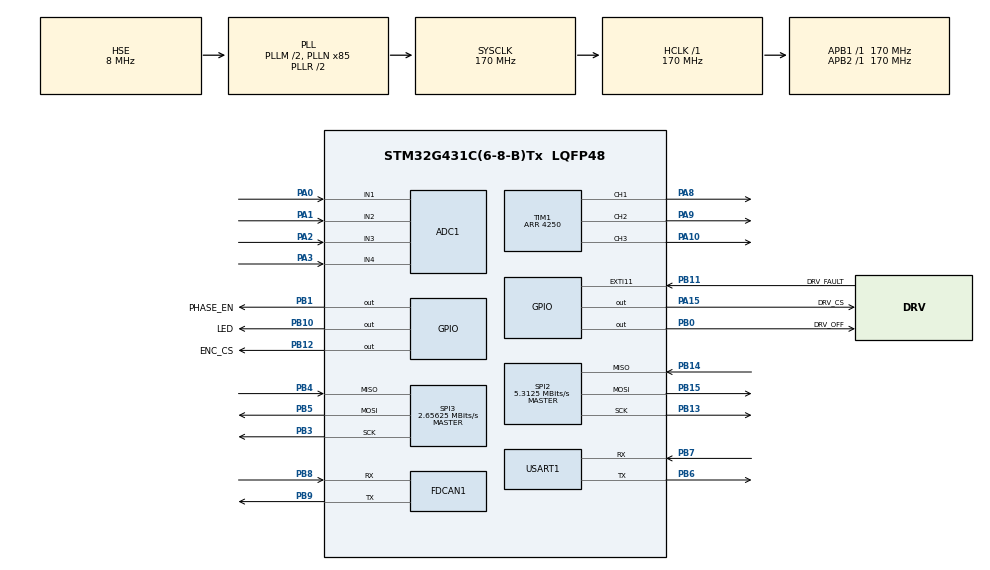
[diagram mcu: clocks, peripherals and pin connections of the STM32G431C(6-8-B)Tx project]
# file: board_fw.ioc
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ADC1.Channel-0\#ChannelRegularConversion=ADC_CHANNEL_4
ADC1.EOCSelection=ADC_EOC_SEQ_CONV
ADC1.EnableInjectedConversion=ENABLE
ADC1.ExternalTrigInjecConv=ADC_EXTERNALTRIGINJEC_T1_CC4
ADC1.InjNumberOfConversion=3
ADC1.InjectedChannel-1\#ChannelInjectedConversion=ADC_CHANNEL_1
ADC1.InjectedChannel-2\#ChannelInjectedConversion=ADC_CHANNEL_2
ADC1.InjectedChannel-3\#ChannelInjectedConversion=ADC_CHANNEL_3
ADC1.InjectedOffsetNumber-1\#ChannelInjectedConversion=ADC_OFFSET_NONE
ADC1.InjectedOffsetNumber-2\#ChannelInjectedConversion=ADC_OFFSET_NONE
ADC1.InjectedOffsetNumber-3\#ChannelInjectedConversion=ADC_OFFSET_NONE
ADC1.InjectedRank-1\#ChannelInjectedConversion=1
ADC1.InjectedRank-2\#ChannelInjectedConversion=2
ADC1.InjectedRank-3\#ChannelInjectedConversion=3
ADC1.InjectedSamplingTime-1\#ChannelInjectedConversion=ADC_SAMPLETIME_12CYCLES_5
ADC1.InjectedSamplingTime-2\#ChannelInjectedConversion=ADC_SAMPLETIME_12CYCLES_5
ADC1.InjectedSamplingTime-3\#ChannelInjectedConversion=ADC_SAMPLETIME_12CYCLES_5
ADC1.NbrOfConversionFlag=1
ADC1.OffsetNumber-0\#ChannelRegularConversion=ADC_OFFSET_NONE
ADC1.Rank-0\#ChannelRegularConversion=1
ADC1.Rank1_Channel=ADC_CHANNEL_1
ADC1.Rank2_Channel=ADC_CHANNEL_2
ADC1.Rank3_Channel=ADC_CHANNEL_3
ADC1.SamplingTime-0\#ChannelRegularConversion=ADC_SAMPLETIME_247CYCLES_5
ADC1.master=1
FDCAN1.CalculateBaudRateNominal=999999
FDCAN1.CalculateTimeBitNominal=1000
FDCAN1.CalculateTimeQuantumNominal=58.82352941176471
FDCAN1.NominalPrescaler=10
FDCAN1.NominalSyncJumpWidth=3
FDCAN1.NominalTimeSeg1=13
FDCAN1.NominalTimeSeg2=3
IWDG.Prescaler=IWDG_PRESCALER_64
IWDG.Reload=999
Mcu.Family=STM32G4
Mcu.Name=STM32G431C(6-8-B)Tx
Mcu.Package=LQFP48
NVIC.ADC1_2_IRQn=true\:0\:0\:false\:false\:true\:true\:true\:true
NVIC.EXTI15_10_IRQn=true\:0\:0\:false\:false\:true\:true\:true\:true
NVIC.FDCAN1_IT0_IRQn=true\:0\:0\:false\:false\:true\:true\:true\:true
NVIC.PriorityGroup=NVIC_PRIORITYGROUP_4
NVIC.TIM6_DAC_IRQn=true\:15\:0\:false\:false\:true\:false\:true\:true
NVIC.TimeBase=TIM6_DAC_IRQn
NVIC.TimeBaseIP=TIM6
NVIC.USART1_IRQn=true\:0\:0\:false\:false\:true\:true\:true\:true
PA0.Mode=IN1-Single-Ended
PA0.Signal=ADC1_IN1
PA1.Mode=IN2-Single-Ended
PA1.Signal=ADC1_IN2
PA10.Signal=S_TIM1_CH3
PA13.Mode=Serial_Wire
PA13.Signal=SYS_JTMS-SWDIO
PA14.Mode=Serial_Wire
PA14.Signal=SYS_JTCK-SWCLK
PA15.GPIO_Label=DRV_CS
PA15.PinState=GPIO_PIN_SET
PA15.Signal=GPIO_Output
PA2.Mode=IN3-Single-Ended
PA2.Signal=ADC1_IN3
PA3.Mode=IN4-Single-Ended
PA3.Signal=ADC1_IN4
PA8.Signal=S_TIM1_CH1
PA9.Signal=S_TIM1_CH2
PB0.GPIO_Label=DRV_OFF
PB0.PinState=GPIO_PIN_SET
PB0.Signal=GPIO_Output
PB1.GPIO_Label=PHASE_EN
PB1.Signal=GPIO_Output
PB10.GPIO_Label=LED
PB10.Signal=GPIO_Output
PB11.GPIO_Label=DRV_FAULT
PB11.GPIO_ModeDefaultEXTI=GPIO_MODE_IT_FALLING
PB11.Signal=GPXTI11
PB12.GPIO_Label=ENC_CS
PB12.PinState=GPIO_PIN_SET
PB12.Signal=GPIO_Output
PB13.Mode=Full_Duplex_Master
PB13.Signal=SPI2_SCK
PB14.Mode=Full_Duplex_Master
PB14.Signal=SPI2_MISO
PB15.Mode=Full_Duplex_Master
PB15.Signal=SPI2_MOSI
PB3.Mode=Full_Duplex_Master
PB3.Signal=SPI3_SCK
PB4.Mode=Full_Duplex_Master
PB4.Signal=SPI3_MISO
PB5.Mode=Full_Duplex_Master
PB5.Signal=SPI3_MOSI
PB6.Mode=Asynchronous
PB6.Signal=USART1_TX
PB7.Mode=Asynchronous
PB7.Signal=USART1_RX
PB8-BOOT0.Mode=FDCAN_Activate
PB8-BOOT0.Signal=FDCAN1_RX
PB9.Mode=FDCAN_Activate
PB9.Signal=FDCAN1_TX
PF0-OSC_IN.Mode=HSE-External-Oscillator
PF0-OSC_IN.Signal=RCC_OSC_IN
PF1-OSC_OUT.Mode=HSE-External-Oscillator
PF1-OSC_OUT.Signal=RCC_OSC_OUT
ProjectManager.HeapSize=0x200
ProjectManager.StackSize=0x400
ProjectManager.TargetToolchain=STM32CubeIDE
RCC.ADC12Freq_Value=170000000
RCC.AHBFreq_Value=170000000
RCC.APB1Freq_Value=170000000
RCC.APB1TimFreq_Value=170000000
RCC.APB2Freq_Value=170000000
RCC.APB2TimFreq_Value=170000000
RCC.CK48CLockSelection=RCC_USBCLKSOURCE_HSI48
RCC.CortexFreq_Value=170000000
RCC.EXTERNAL_CLOCK_VALUE=12288000
RCC.HCLKFreq_Value=170000000
RCC.HSE_VALUE=8000000
RCC.HSI48_VALUE=48000000
RCC.HSI_VALUE=16000000
RCC.LSE_VALUE=32768
RCC.PLLM=RCC_PLLM_DIV2
RCC.PLLN=85
RCC.PLLSourceVirtual=RCC_PLLSOURCE_HSE
RCC.SYSCLKFreq_VALUE=170000000
RCC.SYSCLKSource=RCC_SYSCLKSOURCE_PLLCLK
RCC.USBFreq_Value=48000000
RCC.VCOOutputFreq_Value=340000000
SH.S_TIM1_CH1.0=TIM1_CH1,PWM Generation1 CH1
SH.S_TIM1_CH2.0=TIM1_CH2,PWM Generation2 CH2
SH.S_TIM1_CH3.0=TIM1_CH3,PWM Generation3 CH3
SPI2.BaudRatePrescaler=SPI_BAUDRATEPRESCALER_32
SPI2.CLKPhase=SPI_PHASE_1EDGE
SPI2.CLKPolarity=SPI_POLARITY_HIGH
SPI2.CalculateBaudRate=5.3125 MBits/s
SPI2.DataSize=SPI_DATASIZE_8BIT
SPI2.Direction=SPI_DIRECTION_2LINES
SPI2.Mode=SPI_MODE_MASTER
SPI2.VirtualType=VM_MASTER
SPI3.BaudRatePrescaler=SPI_BAUDRATEPRESCALER_64
SPI3.CLKPhase=SPI_PHASE_2EDGE
SPI3.CalculateBaudRate=2.65625 MBits/s
SPI3.DataSize=SPI_DATASIZE_16BIT
SPI3.Direction=SPI_DIRECTION_2LINES
SPI3.Mode=SPI_MODE_MASTER
SPI3.VirtualType=VM_MASTER
TIM1.Channel-PWM\ Generation1\ CH1=TIM_CHANNEL_1
TIM1.Channel-PWM\ Generation2\ CH2=TIM_CHANNEL_2
TIM1.Channel-PWM\ Generation3\ CH3=TIM_CHANNEL_3
TIM1.Channel-PWM\ Generation4\ No\ Output=TIM_CHANNEL_4
TIM1.CounterMode=TIM_COUNTERMODE_CENTERALIGNED1
TIM1.PeriodNoDither=4250
USART1.VirtualMode-Asynchronous=VM_ASYNC
VP_IWDG_VS_IWDG.Mode=IWDG_Activate
VP_SYS_VS_DBSignals.Mode=DisableDeadBatterySignals
VP_SYS_VS_tim6.Mode=TIM6
VP_TIM1_VS_ClockSourceINT.Mode=Internal
VP_TIM1_VS_no_output4.Mode=PWM Generation4 No Output
board=custom

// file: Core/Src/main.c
/* USER CODE BEGIN Header */
/**
  ******************************************************************************
  * @file           : main.c
  * @brief          : Main program body
  ******************************************************************************
  * @attention
  *
  * Copyright (c) 2026 STMicroelectronics.
  * All rights reserved.
  *
  * This software is licensed under terms that can be found in the LICENSE file
  * in the root directory of this software component.
  * If no LICENSE file comes with this software, it is provided AS-IS.
  *
  ******************************************************************************
  */
/* USER CODE END Header */
#include "main.h"
#include "adc.h"
#include "fdcan.h"
#include "iwdg.h"
#include "spi.h"
#include "tim.h"
#include "usart.h"
#include "gpio.h"

/* USER CODE BEGIN Includes */
#include "app.h"
/* USER CODE END Includes */

void SystemClock_Config(void);

int main(void)
{

  /* MCU Configuration--------------------------------------------------------*/

  /* Reset of all peripherals, Initializes the Flash interface and the Systick. */
  HAL_Init();

  /* USER CODE BEGIN Init */

  //Debug block DBGMCU stops TIM1 while the core is halted (to handle the case where TIM1 keeps the motor on while the CPU is off since TIM1 is separate
  //hardware and keeps running). It also disables the outputs while halted, as if MOE (Main Output Enable) were cleared. MOE is TIM1's master switch
  __HAL_DBGMCU_FREEZE_TIM1();
  __HAL_DBGMCU_FREEZE_IWDG();
  /* USER CODE END Init */

  /* Configure the system clock */
  SystemClock_Config();

  /* Initialize all configured peripherals */
  MX_GPIO_Init();
  MX_ADC1_Init();
  MX_FDCAN1_Init();
  MX_SPI2_Init();
  MX_SPI3_Init();
  MX_TIM1_Init();
  MX_USART1_UART_Init();
  MX_IWDG_Init();
  /* USER CODE BEGIN 2 */
  app_main();
  /* USER CODE END 2 */

  /* Infinite loop */
  while (1)
  {

  }
}

void SystemClock_Config(void)
{
  RCC_OscInitTypeDef RCC_OscInitStruct = {0};
  RCC_ClkInitTypeDef RCC_ClkInitStruct = {0};

  /** Configure the main internal regulator output voltage
  */
  HAL_PWREx_ControlVoltageScaling(PWR_REGULATOR_VOLTAGE_SCALE1_BOOST);

  /** Initializes the RCC Oscillators according to the specified parameters
  * in the RCC_OscInitTypeDef structure.
  */
  RCC_OscInitStruct.OscillatorType = RCC_OSCILLATORTYPE_LSI|RCC_OSCILLATORTYPE_HSE;
  RCC_OscInitStruct.HSEState = RCC_HSE_ON;
  RCC_OscInitStruct.LSIState = RCC_LSI_ON;
  RCC_OscInitStruct.PLL.PLLState = RCC_PLL_ON;
  RCC_OscInitStruct.PLL.PLLSource = RCC_PLLSOURCE_HSE;
  RCC_OscInitStruct.PLL.PLLM = RCC_PLLM_DIV2;
  RCC_OscInitStruct.PLL.PLLN = 85;
  RCC_OscInitStruct.PLL.PLLP = RCC_PLLP_DIV2;
  RCC_OscInitStruct.PLL.PLLQ = RCC_PLLQ_DIV2;
  RCC_OscInitStruct.PLL.PLLR = RCC_PLLR_DIV2;
  if (HAL_RCC_OscConfig(&RCC_OscInitStruct) != HAL_OK)
  {
    Error_Handler();
  }

  /** Initializes the CPU, AHB and APB buses clocks
  */
  RCC_ClkInitStruct.ClockType = RCC_CLOCKTYPE_HCLK|RCC_CLOCKTYPE_SYSCLK
                              |RCC_CLOCKTYPE_PCLK1|RCC_CLOCKTYPE_PCLK2;
  RCC_ClkInitStruct.SYSCLKSource = RCC_SYSCLKSOURCE_PLLCLK;
  RCC_ClkInitStruct.AHBCLKDivider = RCC_SYSCLK_DIV1;
  RCC_ClkInitStruct.APB1CLKDivider = RCC_HCLK_DIV1;
  RCC_ClkInitStruct.APB2CLKDivider = RCC_HCLK_DIV1;

  if (HAL_RCC_ClockConfig(&RCC_ClkInitStruct, FLASH_LATENCY_4) != HAL_OK)
  {
    Error_Handler();
  }
}

void HAL_TIM_PeriodElapsedCallback(TIM_HandleTypeDef *htim)
{
  if (htim->Instance == TIM6)
  {
    HAL_IncTick();
  }
}

void Error_Handler(void)
{
  /* USER CODE BEGIN Error_Handler_Debug */
  /* User can add his own implementation to report the HAL error return state */
  DRV_OFF_GPIO_Port->BSRR = DRV_OFF_Pin;
  PHASE_EN_GPIO_Port->BSRR = PHASE_EN_Pin << 16;
  __disable_irq();
  while (1)
  {
  }
  /* USER CODE END Error_Handler_Debug */
}
